# AT91SAM9G10 register map
Vendor: Atmel; File version: 20130207
Atmel AT91SAM9G10 device: ARM926EJ Embedded Microprocessor Unit, 266MHz, LCD, USB, 217 Pins (refer to http://www.atmel.com/devices/SAM9G10.aspx for more)
CPU: 
Registers are 32-bit, read-write, no defined reset value unless marked. A register's access mark holds for its fields unless they carry their own. Offsets are from the block's base; lines under a group give offsets from that group; [hi:lo] are bit positions; {n}, {i} and the like mark numbered series; 'fields as' and 'values as' point back to an identical list; <NAME> marks a mode.

## Memory map
0x00500000 UHP size 0x100000 — USB Host Port
0x00600000 LCDC size 0x100000 — LCD Controller
0xFFFA0000 TC0 size 0x4000 — Timer Counter 0
0xFFFA4000 UDP size 0x4000 — USB Device Port
0xFFFA8000 MCI size 0x4000 — MultiMedia Card Interface
0xFFFAC000 TWI size 0x4000 — Two-wire Interface
0xFFFB0000 USART0 size 0x4000 — Universal Synchronous Asynchronous Receiver Transmitter 0
0xFFFB4000 USART1 size 0x4000 — Universal Synchronous Asynchronous Receiver Transmitter 1
0xFFFB8000 USART2 size 0x4000 — Universal Synchronous Asynchronous Receiver Transmitter 2
0xFFFBC000 SSC0 size 0x4000 — Synchronous Serial Controller 0
0xFFFC0000 SSC1 size 0x4000 — Synchronous Serial Controller 1
0xFFFC4000 SSC2 size 0x4000 — Synchronous Serial Controller 2
0xFFFC8000 SPI0 size 0x4000 — Serial Peripheral Interface 0
0xFFFCC000 SPI1 size 0x4000 — Serial Peripheral Interface 1
0xFFFFEA00 SDRAMC size 0x200 — SDRAM Controller
0xFFFFEC00 SMC size 0x200 — Static Memory Controller
0xFFFFEE00 MATRIX size 0x200 — AHB Bus Matrix
0xFFFFF000 AIC size 0x200 — Advanced Interrupt Controller
0xFFFFF200 DBGU size 0x200 — Debug Unit
0xFFFFF400 PIOA size 0x200 — Parallel Input/Output Controller A
0xFFFFF600 PIOB size 0x200 — Parallel Input/Output Controller B
0xFFFFF800 PIOC size 0x200 — Parallel Input/Output Controller C
0xFFFFFC00 PMC size 0x200 — Power Management Controller
0xFFFFFD00 RSTC size 0x200 — Reset Controller
0xFFFFFD10 SHDWC size 0x200 — Shutdown Controller
0xFFFFFD20 RTT size 0x200 — Real-time Timer
0xFFFFFD30 PIT size 0x200 — Periodic Interval Timer
0xFFFFFD40 WDT size 0x200 — Watchdog Timer
0xFFFFFD50 GPBR size 0x200 — General Purpose Backup Register

## Interrupts
0 FIQ (AIC)
1 DBGU
2 PIOA
3 PIOB
4 PIOC
6 USART0
7 USART1
8 USART2
9 MCI
10 UDP
11 TWI
12 SPI0
13 SPI1
14 SSC0
15 SSC1
16 SSC2
17 TC0
18 TC1 (TC0)
19 TC2 (TC0)
20 UHP
21 LCDC
29 IRQ0 (AIC)
30 IRQ1 (AIC)
31 IRQ2 (AIC)

## UDP — USB Device Port
Base 0xFFFA4000; register names take the prefix UDP_
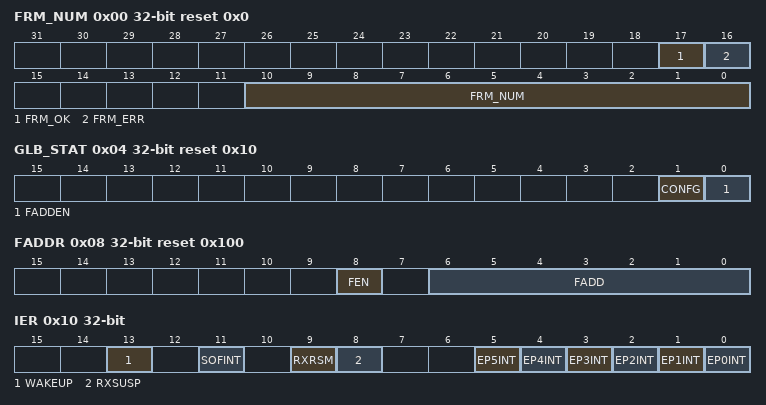
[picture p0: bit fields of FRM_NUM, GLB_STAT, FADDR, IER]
0x00 FRM_NUM ro reset 0x0 — Frame Number Register
  [17] FRM_OK — Frame OK
  [16] FRM_ERR — Frame Error
  [10:0] FRM_NUM — Frame Number as Defined in the Packet Field Formats
0x04 GLB_STAT reset 0x10 — Global State Register
  [1] CONFG — Configured
  [0] FADDEN — Function Address Enable
0x08 FADDR reset 0x100 — Function Address Register
  [8] FEN — Function Enable
  [6:0] FADD — Function Address Value
0x10 IER wo — Interrupt Enable Register
  [13] WAKEUP — Enable UDP bus Wakeup Interrupt
  [11] SOFINT — Enable Start Of Frame Interrupt
  [9] RXRSM — Enable UDP Resume Interrupt
  [8] RXSUSP — Enable UDP Suspend Interrupt
  [5] EP5INT — Enable Endpoint 5 Interrupt
  [4] EP4INT — Enable Endpoint 4 Interrupt
  [3] EP3INT — Enable Endpoint 3 Interrupt
  [2] EP2INT — Enable Endpoint 2Interrupt
  [1] EP1INT — Enable Endpoint 1 Interrupt
  [0] EP0INT — Enable Endpoint 0 Interrupt
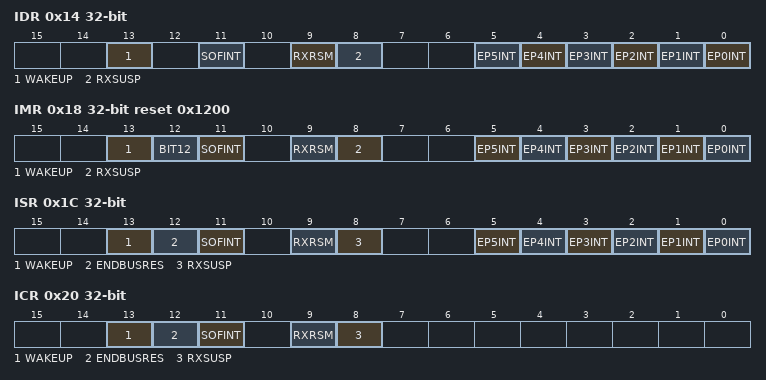
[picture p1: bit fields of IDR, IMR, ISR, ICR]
0x14 IDR wo — Interrupt Disable Register
  [13] WAKEUP — Disable USB Bus Interrupt
  [11] SOFINT — Disable Start Of Frame Interrupt
  [9] RXRSM — Disable UDP Resume Interrupt
  [8] RXSUSP — Disable UDP Suspend Interrupt
  [n] EP{n}INT (n=0..5) — Disable Endpoint {n} Interrupt
0x18 IMR ro reset 0x1200 — Interrupt Mask Register
  [13] WAKEUP — USB Bus WAKEUP Interrupt
  [12] BIT12 — UDP_IMR Bit 12
  [11] SOFINT — Mask Start Of Frame Interrupt
  [9] RXRSM — Mask UDP Resume Interrupt.
  [8] RXSUSP — Mask UDP Suspend Interrupt
  [n] EP{n}INT (n=0..5) — Mask Endpoint {n} Interrupt
0x1C ISR ro — Interrupt Status Register
  [13] WAKEUP — UDP Resume Interrupt Status
  [12] ENDBUSRES — End of BUS Reset Interrupt Status
  [11] SOFINT — Start of Frame Interrupt Status
  [9] RXRSM — UDP Resume Interrupt Status
  [8] RXSUSP — UDP Suspend Interrupt Status
  [n] EP{n}INT (n=0..5) — Endpoint {n} Interrupt Status
0x20 ICR wo — Interrupt Clear Register
  [13] WAKEUP — Clear Wakeup Interrupt
  [12] ENDBUSRES — Clear End of Bus Reset Interrupt
  [11] SOFINT — Clear Start Of Frame Interrupt
  [9] RXRSM — Clear UDP Resume Interrupt
  [8] RXSUSP — Clear UDP Suspend Interrupt
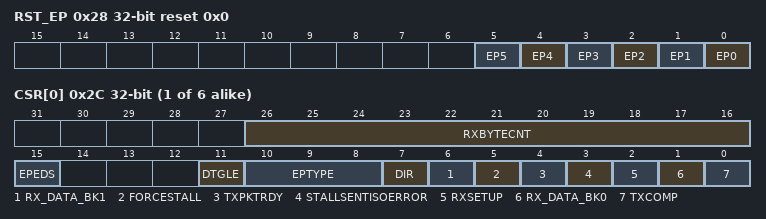
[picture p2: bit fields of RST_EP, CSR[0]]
0x28 RST_EP reset 0x0 — Reset Endpoint Register
  [n] EP{n} (n=0..5) — Reset Endpoint {n}
{0x2C+4i} CSR[{i}] (i=0..5) — Endpoint Control and Status Register (ept_num = 0)
  [26:16] RXBYTECNT — Number of Bytes Available in the FIFO
  [15] EPEDS — Endpoint Enable Disable
  [11] DTGLE — Data Toggle
  [10:8] EPTYPE — Endpoint Type
  [7] DIR — Transfer Direction (only available for control endpoints)
  [6] RX_DATA_BK1 — Receive Data Bank 1 (only used by endpoints with ping-pong attributes)
  [5] FORCESTALL — Force Stall (used by Control, Bulk and Isochronous Endpoints)
  [4] TXPKTRDY — Transmit Packet Ready
  [3] STALLSENTISOERROR
  [2] RXSETUP — Received Setup
  [1] RX_DATA_BK0 — Receive Data Bank 0
  [0] TXCOMP — Generates an IN Packet with Data Previously Written in the DPR
{0x4C+4i} FDR[{i}] (i=0..5) — Endpoint FIFO Data Register (ept_num = 0)
  [7:0] FIFO_DATA — FIFO Data Value
0x74 TXVC reset 0x0 — Transceiver Control Register
  [8] TXVDIS — Transceiver Disable
